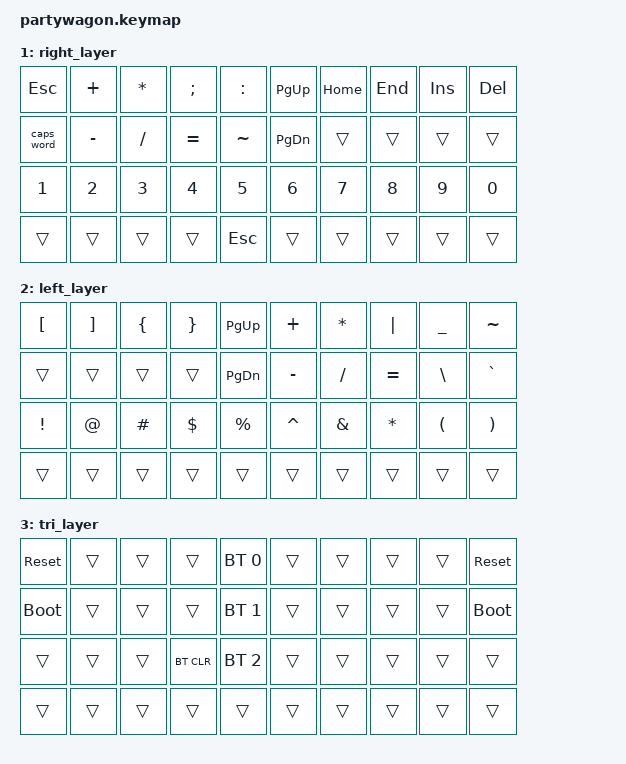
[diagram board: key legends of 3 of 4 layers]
// Copyright (c) 2022 The ZMK Contributors
// SPDX-License-Identifier: MIT

#include <behaviors.dtsi>
#include <dt-bindings/zmk/keys.h>
#include <dt-bindings/zmk/bt.h>

// Home row mods macro
#define HRML(k1,k2,k3,k4) &ht LSHFT k1  &ht LALT k2  &ht LCTRL k3  &ht LGUI k4
#define HRMR(k1,k2,k3,k4) &ht RGUI k1  &ht RCTRL k2  &ht RALT k3  &ht RSHFT k4

/ {
    behaviors {
        ht: hold_tap {
            label = "hold_tap";
            compatible = "zmk,behavior-hold-tap";
            #binding-cells = <2>;
            flavor = "tap-preferred";
            tapping-term-ms = <220>;
            quick-tap-ms = <150>;
            global-quick-tap;
            bindings = <&kp>, <&kp>;
        };
    };

    conditional_layers {
        compatible = "zmk,conditional-layers";
        tri_layer {
            if-layers = <1 2>;
            then-layer = <3>;
        };
    };

    keymap {
        compatible = "zmk,keymap";
        default_layer {
            bindings = <
        //╭──────────┬──────────┬──────────┬──────────┬──────────╮   ╭──────────┬──────────┬──────────┬──────────┬──────────╮
        //│  Q       │  W       │  E       │  R       │  T       │   │  Y       │  U       │  I       │  O       │  P       │
            &kp Q      &kp W      &kp E      &kp R      &kp T          &kp Y      &kp U      &kp I      &kp O      &kp P
        //├──────────┼──────────┼──────────┼──────────┼──────────┤   ├──────────┼──────────┼──────────┼──────────┼──────────┤
        //│  A       │  S       │  D       │  F       │  G       │   │  H       │  J       │  K       │  L       │ ' "      │
            HRML(A,        S,         D,         F)     &kp G          &kp H      HRMR(J,        K,         L,        SQT)
        //├──────────┼──────────┼──────────┼──────────┼──────────┤   ├──────────┼──────────┼──────────┼──────────┼──────────┤
        //│  Z       │  X       │  C       │  V       │  B       │   │  N       │  M       │ , <      │ . >      │ / ?      │
            &kp Z      &kp X      &kp C      &kp V      &kp B          &kp N      &kp M      &kp COMMA  &kp DOT    &kp FSLH
        //├──────────┼──────────┼──────────┼──────────┼──────────┤   ├──────────┼──────────┼──────────┼──────────┼──────────┤
	//│          │  LEFT    │ RIGHT    │          │          │   │          │          │    DOWN  │   UP     │          │
           &kp LSHFT   &kp LARW   &kp RARW   &lt 2 TAB   &kp SPACE    &kp SPACE  &lt 1 BSPC  &kp DARW   &kp UARW   &kp ENTER
        //╰──────────┴──────────┴──────────┴──────────┴──────────╯   ╰──────────┴──────────┴──────────┴──────────┴──────────╯
            >;
        };

        right_layer {
            bindings = <
        //╭──────────┬──────────┬──────────┬──────────┬──────────╮   ╭──────────┬──────────┬──────────┬──────────┬──────────╮
        //│ ESCAPE   │  +       │  *       │  ;       │   :      │   │PAGE UP   │ HOME     │ END      │ INSERT   │  DELETE  │
            &kp ESC   &kp PLUS   &kp ASTRK   &kp SEMI   &kp COLON     &kp PG_UP  &kp HOME   &kp END     &kp INS    &kp DEL
        //├──────────┼──────────┼──────────┼──────────┼──────────┤   ├──────────┼──────────┼──────────┼──────────┼──────────┤
        //│ CAPS     │  -       │  /       │  =       │   ~      │   │PAGE DOWN │          │          │          │          │
           &caps_word  &kp MINUS  &kp FSLH   &kp EQUAL  &kp TILDE     &kp PG_DN   &trans     &trans     &trans     &trans
        //├──────────┼──────────┼──────────┼──────────┼──────────┤   ├──────────┼──────────┼──────────┼──────────┼──────────┤
        //│    1     │   2      │  3       │  4       │  5       │   │    6     │   7      │   8      │    9     │   0      │
             &kp N1    &kp N2     &kp N3     &kp N4     &kp N5          &kp N6    &kp N7     &kp N8     &kp N9     &kp N0    
        //├──────────┼──────────┼──────────┼──────────┼──────────┤   ├──────────┼──────────┼──────────┼──────────┼──────────┤
	//│          │          │          │          │          │   │          │          │          │          │          │
            &trans     &trans     &trans     &trans     &kp ESC        &trans     &trans     &trans     &trans     &trans
        //╰──────────┴──────────┴──────────┴──────────┴──────────╯   ╰──────────┴──────────┴──────────┴──────────┴──────────╯
            >;
        };

        left_layer {
            bindings = <
        //╭──────────┬──────────┬──────────┬──────────┬──────────╮   ╭──────────┬──────────┬──────────┬──────────┬──────────╮
        //│  [       │  ]       │  {       │  }       │ PAGE UP  │   │  +       │  *       │  |       │  _       │  ~       │
            &kp LBKT   &kp RBKT   &kp LBRC   &kp RBRC  &kp PG_UP       &kp PLUS  &kp ASTRK  &kp PIPE   &kp UNDER  &kp TILDE
        //├──────────┼──────────┼──────────┼──────────┼──────────┤   ├──────────┼──────────┼──────────┼──────────┼──────────┤
        //│          │          │          │          │PAGE DOWN │   │  -       │  /       │  =       │  \       │  `       │
            &trans     &trans     &trans     &trans    &kp PG_DN      &kp MINUS   &kp FSLH   &kp EQUAL  &kp BSLH   &kp GRAVE
        //├──────────┼──────────┼──────────┼──────────┼──────────┤   ├──────────┼──────────┼──────────┼──────────┼──────────┤
        //│  !       │  @       │  #       │  $       │  %       │   │  ^       │  &       │  *       │  (       │   )      │
            &kp EXCL   &kp AT     &kp HASH   &kp DLLR   &kp PRCNT      &kp CARET  &kp AMPS  &kp ASTRK   &kp LPAR   &kp RPAR
        //├──────────┼──────────┼──────────┼──────────┼──────────┤   ├──────────┼──────────┼──────────┼──────────┼──────────┤
	//│          │          │          │          │          │   │          │          │          │          │          │
            &trans     &trans     &trans     &trans     &trans         &trans     &trans     &trans     &trans     &trans
        //╰──────────┴──────────┴──────────┴──────────┴──────────╯   ╰──────────┴──────────┴──────────┴──────────┴──────────╯
            >;
        };

        tri_layer {
            bindings = <
        //╭──────────┬──────────┬──────────┬──────────┬──────────╮   ╭──────────┬──────────┬──────────┬──────────┬──────────╮
        //│ RESET    │          │          │          │PROFILE 0 │   │          │          │          │          │  RESET   │
           &sys_reset  &trans     &trans     &trans    &bt BT_SEL 0    &trans     &trans     &trans     &trans    &sys_reset
        //├──────────┼──────────┼──────────┼──────────┼──────────┤   ├──────────┼──────────┼──────────┼──────────┼──────────┤
        //│BOOTLOADER│          │          │          │PROFILE 1 │   │          │          │          │          │BOOTLOADER│
          &bootloader  &trans     &trans     &trans    &bt BT_SEL 1    &trans     &trans     &trans     &trans    &bootloader
        //├──────────┼──────────┼──────────┼──────────┼──────────┤   ├──────────┼──────────┼──────────┼──────────┼──────────┤
        //│          │          │          │ CLEAR BT │PROFILE 2 │   │          │          │          │          │          │
            &trans     &trans     &trans    &bt BT_CLR &bt BT_SEL 2    &trans     &trans     &trans     &trans     &trans
        //├──────────┼──────────┼──────────┼──────────┼──────────┤   ├──────────┼──────────┼──────────┼──────────┼──────────┤
	//│          │          │          │          │          │   │          │          │          │          │          │
            &trans     &trans     &trans     &trans     &trans         &trans     &trans     &trans     &trans     &trans
        //╰──────────┴──────────┴──────────┴──────────┴──────────╯   ╰──────────┴──────────┴──────────┴──────────┴──────────╯
            >;
        };
    };
};
